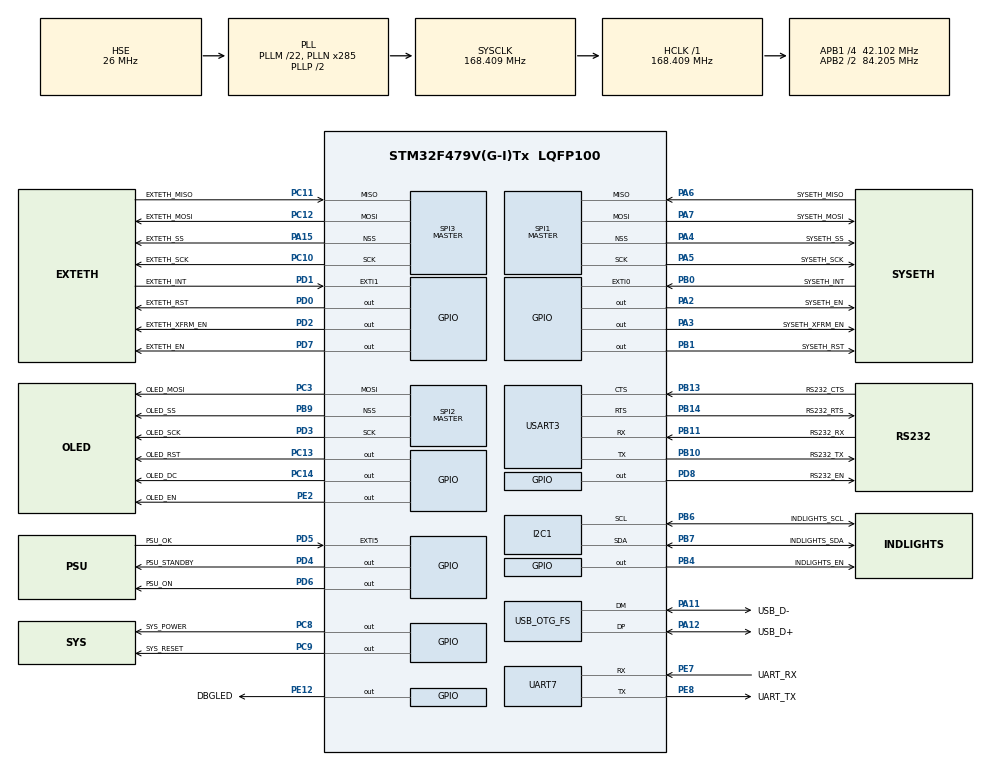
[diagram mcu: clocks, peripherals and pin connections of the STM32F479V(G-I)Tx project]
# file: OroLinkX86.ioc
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Mcu.Family=STM32F4
Mcu.Name=STM32F479V(G-I)Tx
Mcu.Package=LQFP100
NVIC.EXTI0_IRQn=true\:0\:0\:false\:false\:true\:true\:true\:true
NVIC.EXTI1_IRQn=true\:0\:0\:false\:false\:true\:true\:true\:true
NVIC.OTG_FS_IRQn=true\:0\:0\:false\:false\:true\:false\:true\:true
NVIC.PriorityGroup=NVIC_PRIORITYGROUP_4
PA11.GPIO_Label=USB_D-
PA11.Mode=Device_Only
PA11.Signal=USB_OTG_FS_DM
PA12.GPIO_Label=USB_D+
PA12.Mode=Device_Only
PA12.Signal=USB_OTG_FS_DP
PA13.GPIO_Label=SWDIO
PA13.Mode=Trace_Asynchronous_SW
PA13.Signal=SYS_JTMS-SWDIO
PA14.GPIO_Label=SWCLK
PA14.Mode=Trace_Asynchronous_SW
PA14.Signal=SYS_JTCK-SWCLK
PA15.GPIO_Label=EXTETH_SS
PA15.Mode=NSS_Signal_Hard_Output
PA15.Signal=SPI3_NSS
PA2.GPIO_Label=SYSETH_EN
PA2.Signal=GPIO_Output
PA3.GPIO_Label=SYSETH_XFRM_EN
PA3.Signal=GPIO_Output
PA4.GPIO_Label=SYSETH_SS
PA4.Mode=NSS_Signal_Hard_Output
PA4.Signal=SPI1_NSS
PA5.GPIO_Label=SYSETH_SCK
PA5.Mode=Full_Duplex_Master
PA5.Signal=SPI1_SCK
PA6.GPIO_Label=SYSETH_MISO
PA6.Mode=Full_Duplex_Master
PA6.Signal=SPI1_MISO
PA7.GPIO_Label=SYSETH_MOSI
PA7.Mode=Full_Duplex_Master
PA7.Signal=SPI1_MOSI
PB0.GPIO_Label=SYSETH_INT
PB0.Signal=GPXTI0
PB1.GPIO_Label=SYSETH_RST
PB1.GPIO_PuPd=GPIO_NOPULL
PB1.PinState=GPIO_PIN_RESET
PB1.Signal=GPIO_Output
PB10.GPIO_Label=RS232_TX
PB10.Mode=Asynchronous
PB10.Signal=USART3_TX
PB11.GPIO_Label=RS232_RX
PB11.Mode=Asynchronous
PB11.Signal=USART3_RX
PB13.GPIO_Label=RS232_CTS
PB13.Mode=CTS_RTS
PB13.Signal=USART3_CTS
PB14.GPIO_Label=RS232_RTS
PB14.Mode=CTS_RTS
PB14.Signal=USART3_RTS
PB3.GPIO_Label=SWO
PB3.Mode=Trace_Asynchronous_SW
PB3.Signal=SYS_JTDO-SWO
PB4.GPIO_Label=INDLIGHTS_EN
PB4.Signal=GPIO_Output
PB6.GPIO_Label=INDLIGHTS_SCL
PB6.Mode=I2C
PB6.Signal=I2C1_SCL
PB7.GPIO_Label=INDLIGHTS_SDA
PB7.Mode=I2C
PB7.Signal=I2C1_SDA
PB9.GPIO_Label=OLED_SS
PB9.Mode=NSS_Signal_Hard_Output
PB9.Signal=SPI2_NSS
PC10.GPIO_Label=EXTETH_SCK
PC10.Mode=Full_Duplex_Master
PC10.Signal=SPI3_SCK
PC11.GPIO_Label=EXTETH_MISO
PC11.Mode=Full_Duplex_Master
PC11.Signal=SPI3_MISO
PC12.GPIO_Label=EXTETH_MOSI
PC12.Mode=Full_Duplex_Master
PC12.Signal=SPI3_MOSI
PC13.GPIO_Label=OLED_RST
PC13.GPIO_ModeDefaultOutputPP=GPIO_MODE_OUTPUT_PP
PC13.GPIO_PuPd=GPIO_NOPULL
PC13.GPIO_Speed=GPIO_SPEED_FREQ_LOW
PC13.Signal=GPIO_Output
PC14/OSC32_IN.GPIO_Label=OLED_DC
PC14/OSC32_IN.Signal=GPIO_Output
PC3.GPIO_Label=OLED_MOSI
PC3.Mode=TX_Only_Simplex_Unidirect_Master
PC3.Signal=SPI2_MOSI
PC8.GPIO_Label=SYS_POWER
PC8.Signal=GPIO_Output
PC9.GPIO_Label=SYS_RESET
PC9.Signal=GPIO_Output
PD0.GPIO_Label=EXTETH_RST
PD0.GPIO_PuPd=GPIO_NOPULL
PD0.Signal=GPIO_Output
PD1.GPIO_Label=EXTETH_INT
PD1.Signal=GPXTI1
PD2.GPIO_Label=EXTETH_XFRM_EN
PD2.Signal=GPIO_Output
PD3.GPIO_Label=OLED_SCK
PD3.Mode=TX_Only_Simplex_Unidirect_Master
PD3.Signal=SPI2_SCK
PD4.GPIO_Label=PSU_STANDBY
PD4.Signal=GPIO_Output
PD5.GPIO_Label=PSU_OK
PD5.Signal=GPXTI5
PD6.GPIO_Label=PSU_ON
PD6.Signal=GPIO_Output
PD7.GPIO_Label=EXTETH_EN
PD7.Signal=GPIO_Output
PD8.GPIO_Label=RS232_EN
PD8.Signal=GPIO_Output
PE12.GPIO_Label=DBGLED
PE12.Signal=GPIO_Output
PE2.GPIO_Label=OLED_EN
PE2.Signal=GPIO_Output
PE7.GPIO_Label=UART_RX
PE7.Mode=Asynchronous
PE7.Signal=UART7_RX
PE8.GPIO_Label=UART_TX
PE8.Mode=Asynchronous
PE8.Signal=UART7_TX
PH0/OSC_IN.GPIO_Label=CLOCK_IN
PH0/OSC_IN.Mode=HSE-External-Oscillator
PH0/OSC_IN.Signal=RCC_OSC_IN
PH1/OSC_OUT.Mode=HSE-External-Oscillator
PH1/OSC_OUT.Signal=RCC_OSC_OUT
ProjectManager.HeapSize=0x200
ProjectManager.StackSize=0x400
ProjectManager.TargetToolchain=STM32CubeIDE
RCC.AHBFreq_Value=168409090.9090909
RCC.APB1CLKDivider=RCC_HCLK_DIV4
RCC.APB1Freq_Value=42102272.72727273
RCC.APB1TimFreq_Value=84204545.45454545
RCC.APB2CLKDivider=RCC_HCLK_DIV2
RCC.APB2Freq_Value=84204545.45454545
RCC.APB2TimFreq_Value=168409090.9090909
RCC.CortexFreq_Value=168409090.9090909
RCC.HCLKFreq_Value=168409090.9090909
RCC.HSE_VALUE=26000000
RCC.PLLM=22
RCC.PLLN=285
RCC.PLLQ=7
RCC.PLLSourceVirtual=RCC_PLLSOURCE_HSE
RCC.SYSCLKFreq_VALUE=168409090.9090909
RCC.SYSCLKSource=RCC_SYSCLKSOURCE_PLLCLK
RCC.USBFreq_Value=48116883.116883114
RCC.VCOOutputFreq_Value=336818181.8181818
SPI1.BaudRatePrescaler=SPI_BAUDRATEPRESCALER_2
SPI1.CalculateBaudRate=42.102272 MBits/s
SPI1.Direction=SPI_DIRECTION_2LINES
SPI1.Mode=SPI_MODE_MASTER
SPI1.VirtualNSS=VM_NSSHARD
SPI1.VirtualType=VM_MASTER
SPI2.BaudRatePrescaler=SPI_BAUDRATEPRESCALER_2
SPI2.CalculateBaudRate=21.051136 MBits/s
SPI2.Direction=SPI_DIRECTION_2LINES
SPI2.Mode=SPI_MODE_MASTER
SPI2.VirtualNSS=VM_NSSHARD
SPI2.VirtualType=VM_MASTER
SPI3.BaudRatePrescaler=SPI_BAUDRATEPRESCALER_2
SPI3.CalculateBaudRate=21.051136 MBits/s
SPI3.Direction=SPI_DIRECTION_2LINES
SPI3.Mode=SPI_MODE_MASTER
SPI3.VirtualNSS=VM_NSSHARD
SPI3.VirtualType=VM_MASTER
UART7.VirtualMode=Asynchronous
USART3.VirtualMode=VM_ASYNC
USB_DEVICE.CLASS_NAME_FS=HID
USB_DEVICE.MANUFACTURER_STRING-HID_FS=Oro Operating System
USB_DEVICE.PRODUCT_STRING_HID_FS=Oro Link Emulated HID
USB_DEVICE.VirtualMode-HID_FS=Hid
USB_DEVICE.VirtualModeFS=Hid_FS
USB_OTG_FS.VirtualMode=Device_Only
VP_USB_DEVICE_VS_USB_DEVICE_HID_FS.Mode=HID_FS
board=custom

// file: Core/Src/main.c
/* USER CODE BEGIN Header */
/**
 ******************************************************************************
 * @file           : main.c
 * @brief          : Main program body
 ******************************************************************************
 * @attention
 *
 * Copyright (c) 2023 STMicroelectronics.
 * All rights reserved.
 *
 * This software is licensed under terms that can be found in the LICENSE file
 * in the root directory of this software component.
 * If no LICENSE file comes with this software, it is provided AS-IS.
 *
 ******************************************************************************
 */
/* USER CODE END Header */
#include "main.h"
#include "usb_device.h"

I2C_HandleTypeDef hi2c1;

SPI_HandleTypeDef hspi1;
SPI_HandleTypeDef hspi2;
SPI_HandleTypeDef hspi3;

UART_HandleTypeDef huart7;
UART_HandleTypeDef huart3;

void SystemClock_Config(void);
static void MX_GPIO_Init(void);
static void MX_SPI1_Init(void);
static void MX_SPI2_Init(void);
static void MX_SPI3_Init(void);
static void MX_I2C1_Init(void);
static void MX_UART7_Init(void);
static void MX_USART3_UART_Init(void);

/* USER CODE BEGIN 0 */

int __io_putchar(int ch) {
	// Write character to ITM ch.0
	ITM_SendChar(ch);
	return (ch);
}

/* USER CODE END 0 */

int main(void)
{

  /* MCU Configuration--------------------------------------------------------*/

  /* Reset of all peripherals, Initializes the Flash interface and the Systick. */
  HAL_Init();

  /* Configure the system clock */
  SystemClock_Config();

  /* Initialize all configured peripherals */
  MX_GPIO_Init();
  MX_SPI1_Init();
  MX_SPI2_Init();
  MX_SPI3_Init();
  MX_I2C1_Init();
  MX_UART7_Init();
  MX_USART3_UART_Init();
  MX_USB_DEVICE_Init();

  /* Infinite loop */
  /* USER CODE BEGIN WHILE */
	static unsigned count = 0;
	printf("Hello, Oro");
	while (1) {
    /* USER CODE END WHILE */

    /* USER CODE BEGIN 3 */
		++count;
		HAL_GPIO_TogglePin(DBGLED_GPIO_Port, DBGLED_Pin);
		HAL_Delay(500);

		count += 1;
		count %= 100;

		if (count == 0) {
			HAL_GPIO_TogglePin(PSU_ON_GPIO_Port, PSU_ON_Pin);
		}
	}
  /* USER CODE END 3 */
}

void SystemClock_Config(void)
{
  RCC_OscInitTypeDef RCC_OscInitStruct = {0};
  RCC_ClkInitTypeDef RCC_ClkInitStruct = {0};

  /** Configure the main internal regulator output voltage
  */
  __HAL_RCC_PWR_CLK_ENABLE();
  __HAL_PWR_VOLTAGESCALING_CONFIG(PWR_REGULATOR_VOLTAGE_SCALE1);

  /** Initializes the RCC Oscillators according to the specified parameters
  * in the RCC_OscInitTypeDef structure.
  */
  RCC_OscInitStruct.OscillatorType = RCC_OSCILLATORTYPE_HSE;
  RCC_OscInitStruct.HSEState = RCC_HSE_ON;
  RCC_OscInitStruct.PLL.PLLState = RCC_PLL_ON;
  RCC_OscInitStruct.PLL.PLLSource = RCC_PLLSOURCE_HSE;
  RCC_OscInitStruct.PLL.PLLM = 22;
  RCC_OscInitStruct.PLL.PLLN = 285;
  RCC_OscInitStruct.PLL.PLLP = RCC_PLLP_DIV2;
  RCC_OscInitStruct.PLL.PLLQ = 7;
  RCC_OscInitStruct.PLL.PLLR = 2;
  if (HAL_RCC_OscConfig(&RCC_OscInitStruct) != HAL_OK)
  {
    Error_Handler();
  }

  /** Activate the Over-Drive mode
  */
  if (HAL_PWREx_EnableOverDrive() != HAL_OK)
  {
    Error_Handler();
  }

  /** Initializes the CPU, AHB and APB buses clocks
  */
  RCC_ClkInitStruct.ClockType = RCC_CLOCKTYPE_HCLK|RCC_CLOCKTYPE_SYSCLK
                              |RCC_CLOCKTYPE_PCLK1|RCC_CLOCKTYPE_PCLK2;
  RCC_ClkInitStruct.SYSCLKSource = RCC_SYSCLKSOURCE_PLLCLK;
  RCC_ClkInitStruct.AHBCLKDivider = RCC_SYSCLK_DIV1;
  RCC_ClkInitStruct.APB1CLKDivider = RCC_HCLK_DIV4;
  RCC_ClkInitStruct.APB2CLKDivider = RCC_HCLK_DIV2;

  if (HAL_RCC_ClockConfig(&RCC_ClkInitStruct, FLASH_LATENCY_5) != HAL_OK)
  {
    Error_Handler();
  }
}

static void MX_I2C1_Init(void)
{

  hi2c1.Instance = I2C1;
  hi2c1.Init.ClockSpeed = 100000;
  hi2c1.Init.DutyCycle = I2C_DUTYCYCLE_2;
  hi2c1.Init.OwnAddress1 = 0;
  hi2c1.Init.AddressingMode = I2C_ADDRESSINGMODE_7BIT;
  hi2c1.Init.DualAddressMode = I2C_DUALADDRESS_DISABLE;
  hi2c1.Init.OwnAddress2 = 0;
  hi2c1.Init.GeneralCallMode = I2C_GENERALCALL_DISABLE;
  hi2c1.Init.NoStretchMode = I2C_NOSTRETCH_DISABLE;
  if (HAL_I2C_Init(&hi2c1) != HAL_OK)
  {
    Error_Handler();
  }

}

static void MX_SPI1_Init(void)
{

  /* SPI1 parameter configuration*/
  hspi1.Instance = SPI1;
  hspi1.Init.Mode = SPI_MODE_MASTER;
  hspi1.Init.Direction = SPI_DIRECTION_2LINES;
  hspi1.Init.DataSize = SPI_DATASIZE_8BIT;
  hspi1.Init.CLKPolarity = SPI_POLARITY_LOW;
  hspi1.Init.CLKPhase = SPI_PHASE_1EDGE;
  hspi1.Init.NSS = SPI_NSS_HARD_OUTPUT;
  hspi1.Init.BaudRatePrescaler = SPI_BAUDRATEPRESCALER_2;
  hspi1.Init.FirstBit = SPI_FIRSTBIT_MSB;
  hspi1.Init.TIMode = SPI_TIMODE_DISABLE;
  hspi1.Init.CRCCalculation = SPI_CRCCALCULATION_DISABLE;
  hspi1.Init.CRCPolynomial = 10;
  if (HAL_SPI_Init(&hspi1) != HAL_OK)
  {
    Error_Handler();
  }

}

static void MX_SPI2_Init(void)
{

  /* SPI2 parameter configuration*/
  hspi2.Instance = SPI2;
  hspi2.Init.Mode = SPI_MODE_MASTER;
  hspi2.Init.Direction = SPI_DIRECTION_2LINES;
  hspi2.Init.DataSize = SPI_DATASIZE_8BIT;
  hspi2.Init.CLKPolarity = SPI_POLARITY_LOW;
  hspi2.Init.CLKPhase = SPI_PHASE_1EDGE;
  hspi2.Init.NSS = SPI_NSS_HARD_OUTPUT;
  hspi2.Init.BaudRatePrescaler = SPI_BAUDRATEPRESCALER_2;
  hspi2.Init.FirstBit = SPI_FIRSTBIT_MSB;
  hspi2.Init.TIMode = SPI_TIMODE_DISABLE;
  hspi2.Init.CRCCalculation = SPI_CRCCALCULATION_DISABLE;
  hspi2.Init.CRCPolynomial = 10;
  if (HAL_SPI_Init(&hspi2) != HAL_OK)
  {
    Error_Handler();
  }

}

static void MX_SPI3_Init(void)
{

  /* SPI3 parameter configuration*/
  hspi3.Instance = SPI3;
  hspi3.Init.Mode = SPI_MODE_MASTER;
  hspi3.Init.Direction = SPI_DIRECTION_2LINES;
  hspi3.Init.DataSize = SPI_DATASIZE_8BIT;
  hspi3.Init.CLKPolarity = SPI_POLARITY_LOW;
  hspi3.Init.CLKPhase = SPI_PHASE_1EDGE;
  hspi3.Init.NSS = SPI_NSS_HARD_OUTPUT;
  hspi3.Init.BaudRatePrescaler = SPI_BAUDRATEPRESCALER_2;
  hspi3.Init.FirstBit = SPI_FIRSTBIT_MSB;
  hspi3.Init.TIMode = SPI_TIMODE_DISABLE;
  hspi3.Init.CRCCalculation = SPI_CRCCALCULATION_DISABLE;
  hspi3.Init.CRCPolynomial = 10;
  if (HAL_SPI_Init(&hspi3) != HAL_OK)
  {
    Error_Handler();
  }

}

static void MX_UART7_Init(void)
{

  huart7.Instance = UART7;
  huart7.Init.BaudRate = 115200;
  huart7.Init.WordLength = UART_WORDLENGTH_8B;
  huart7.Init.StopBits = UART_STOPBITS_1;
  huart7.Init.Parity = UART_PARITY_NONE;
  huart7.Init.Mode = UART_MODE_TX_RX;
  huart7.Init.HwFlowCtl = UART_HWCONTROL_NONE;
  huart7.Init.OverSampling = UART_OVERSAMPLING_16;
  if (HAL_UART_Init(&huart7) != HAL_OK)
  {
    Error_Handler();
  }

}

static void MX_USART3_UART_Init(void)
{

  huart3.Instance = USART3;
  huart3.Init.BaudRate = 115200;
  huart3.Init.WordLength = UART_WORDLENGTH_8B;
  huart3.Init.StopBits = UART_STOPBITS_1;
  huart3.Init.Parity = UART_PARITY_NONE;
  huart3.Init.Mode = UART_MODE_TX_RX;
  huart3.Init.HwFlowCtl = UART_HWCONTROL_RTS_CTS;
  huart3.Init.OverSampling = UART_OVERSAMPLING_16;
  if (HAL_UART_Init(&huart3) != HAL_OK)
  {
    Error_Handler();
  }

}

static void MX_GPIO_Init(void)
{
  GPIO_InitTypeDef GPIO_InitStruct = {0};

  /* GPIO Ports Clock Enable */
  __HAL_RCC_GPIOE_CLK_ENABLE();
  __HAL_RCC_GPIOC_CLK_ENABLE();
  __HAL_RCC_GPIOH_CLK_ENABLE();
  __HAL_RCC_GPIOA_CLK_ENABLE();
  __HAL_RCC_GPIOB_CLK_ENABLE();
  __HAL_RCC_GPIOD_CLK_ENABLE();

  /*Configure GPIO pin Output Level */
  HAL_GPIO_WritePin(GPIOE, OLED_EN_Pin|DBGLED_Pin, GPIO_PIN_RESET);

  /*Configure GPIO pin Output Level */
  HAL_GPIO_WritePin(GPIOC, OLED_RST_Pin|OLED_DC_Pin|SYS_POWER_Pin|SYS_RESET_Pin, GPIO_PIN_RESET);

  /*Configure GPIO pin Output Level */
  HAL_GPIO_WritePin(GPIOA, SYSETH_EN_Pin|SYSETH_XFRM_EN_Pin, GPIO_PIN_RESET);

  /*Configure GPIO pin Output Level */
  HAL_GPIO_WritePin(GPIOB, SYSETH_RST_Pin|INDLIGHTS_EN_Pin, GPIO_PIN_RESET);

  /*Configure GPIO pin Output Level */
  HAL_GPIO_WritePin(GPIOD, RS232_EN_Pin|EXTETH_RST_Pin|EXTETH_XFRM_EN_Pin|PSU_STANDBY_Pin
                          |PSU_ON_Pin|EXTETH_EN_Pin, GPIO_PIN_RESET);

  /*Configure GPIO pins : OLED_EN_Pin DBGLED_Pin */
  GPIO_InitStruct.Pin = OLED_EN_Pin|DBGLED_Pin;
  GPIO_InitStruct.Mode = GPIO_MODE_OUTPUT_PP;
  GPIO_InitStruct.Pull = GPIO_NOPULL;
  GPIO_InitStruct.Speed = GPIO_SPEED_FREQ_LOW;
  HAL_GPIO_Init(GPIOE, &GPIO_InitStruct);

  /*Configure GPIO pins : OLED_RST_Pin OLED_DC_Pin SYS_POWER_Pin SYS_RESET_Pin */
  GPIO_InitStruct.Pin = OLED_RST_Pin|OLED_DC_Pin|SYS_POWER_Pin|SYS_RESET_Pin;
  GPIO_InitStruct.Mode = GPIO_MODE_OUTPUT_PP;
  GPIO_InitStruct.Pull = GPIO_NOPULL;
  GPIO_InitStruct.Speed = GPIO_SPEED_FREQ_LOW;
  HAL_GPIO_Init(GPIOC, &GPIO_InitStruct);

  /*Configure GPIO pins : SYSETH_EN_Pin SYSETH_XFRM_EN_Pin */
  GPIO_InitStruct.Pin = SYSETH_EN_Pin|SYSETH_XFRM_EN_Pin;
  GPIO_InitStruct.Mode = GPIO_MODE_OUTPUT_PP;
  GPIO_InitStruct.Pull = GPIO_NOPULL;
  GPIO_InitStruct.Speed = GPIO_SPEED_FREQ_LOW;
  HAL_GPIO_Init(GPIOA, &GPIO_InitStruct);

  /*Configure GPIO pin : SYSETH_INT_Pin */
  GPIO_InitStruct.Pin = SYSETH_INT_Pin;
  GPIO_InitStruct.Mode = GPIO_MODE_IT_RISING;
  GPIO_InitStruct.Pull = GPIO_NOPULL;
  HAL_GPIO_Init(SYSETH_INT_GPIO_Port, &GPIO_InitStruct);

  /*Configure GPIO pins : SYSETH_RST_Pin INDLIGHTS_EN_Pin */
  GPIO_InitStruct.Pin = SYSETH_RST_Pin|INDLIGHTS_EN_Pin;
  GPIO_InitStruct.Mode = GPIO_MODE_OUTPUT_PP;
  GPIO_InitStruct.Pull = GPIO_NOPULL;
  GPIO_InitStruct.Speed = GPIO_SPEED_FREQ_LOW;
  HAL_GPIO_Init(GPIOB, &GPIO_InitStruct);

  /*Configure GPIO pins : RS232_EN_Pin EXTETH_RST_Pin EXTETH_XFRM_EN_Pin PSU_STANDBY_Pin
                           PSU_ON_Pin EXTETH_EN_Pin */
  GPIO_InitStruct.Pin = RS232_EN_Pin|EXTETH_RST_Pin|EXTETH_XFRM_EN_Pin|PSU_STANDBY_Pin
                          |PSU_ON_Pin|EXTETH_EN_Pin;
  GPIO_InitStruct.Mode = GPIO_MODE_OUTPUT_PP;
  GPIO_InitStruct.Pull = GPIO_NOPULL;
  GPIO_InitStruct.Speed = GPIO_SPEED_FREQ_LOW;
  HAL_GPIO_Init(GPIOD, &GPIO_InitStruct);

  /*Configure GPIO pins : EXTETH_INT_Pin PSU_OK_Pin */
  GPIO_InitStruct.Pin = EXTETH_INT_Pin|PSU_OK_Pin;
  GPIO_InitStruct.Mode = GPIO_MODE_IT_RISING;
  GPIO_InitStruct.Pull = GPIO_NOPULL;
  HAL_GPIO_Init(GPIOD, &GPIO_InitStruct);

  /* EXTI interrupt init*/
  HAL_NVIC_SetPriority(EXTI0_IRQn, 0, 0);
  HAL_NVIC_EnableIRQ(EXTI0_IRQn);

  HAL_NVIC_SetPriority(EXTI1_IRQn, 0, 0);
  HAL_NVIC_EnableIRQ(EXTI1_IRQn);

}

void Error_Handler(void)
{
	__disable_irq();
	while (1) {
	}
}
